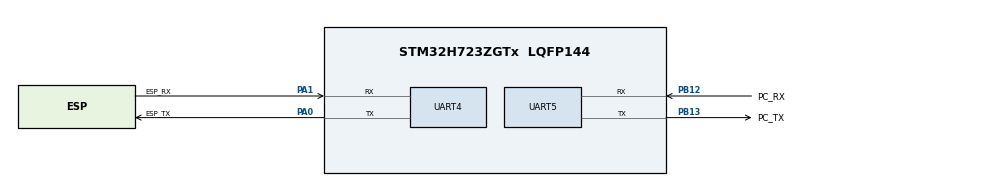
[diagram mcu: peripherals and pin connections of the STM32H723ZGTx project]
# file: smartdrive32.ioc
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CORTEX_M7.default_mode_Activation=1
Dma.Request0=UART4_RX
Dma.Request1=UART5_RX
Dma.UART4_RX.0.Direction=DMA_PERIPH_TO_MEMORY
Dma.UART4_RX.0.EventEnable=DISABLE
Dma.UART4_RX.0.FIFOMode=DMA_FIFOMODE_DISABLE
Dma.UART4_RX.0.Instance=DMA1_Stream0
Dma.UART4_RX.0.MemDataAlignment=DMA_MDATAALIGN_BYTE
Dma.UART4_RX.0.MemInc=DMA_MINC_ENABLE
Dma.UART4_RX.0.Mode=DMA_NORMAL
Dma.UART4_RX.0.PeriphDataAlignment=DMA_PDATAALIGN_BYTE
Dma.UART4_RX.0.PeriphInc=DMA_PINC_DISABLE
Dma.UART4_RX.0.Polarity=HAL_DMAMUX_REQ_GEN_RISING
Dma.UART4_RX.0.Priority=DMA_PRIORITY_LOW
Dma.UART4_RX.0.RequestNumber=1
Dma.UART4_RX.0.SignalID=NONE
Dma.UART4_RX.0.SyncEnable=DISABLE
Dma.UART4_RX.0.SyncPolarity=HAL_DMAMUX_SYNC_NO_EVENT
Dma.UART4_RX.0.SyncRequestNumber=1
Dma.UART4_RX.0.SyncSignalID=NONE
Dma.UART5_RX.1.Direction=DMA_PERIPH_TO_MEMORY
Dma.UART5_RX.1.EventEnable=DISABLE
Dma.UART5_RX.1.FIFOMode=DMA_FIFOMODE_DISABLE
Dma.UART5_RX.1.Instance=DMA1_Stream1
Dma.UART5_RX.1.MemDataAlignment=DMA_MDATAALIGN_BYTE
Dma.UART5_RX.1.MemInc=DMA_MINC_ENABLE
Dma.UART5_RX.1.Mode=DMA_NORMAL
Dma.UART5_RX.1.PeriphDataAlignment=DMA_PDATAALIGN_BYTE
Dma.UART5_RX.1.PeriphInc=DMA_PINC_DISABLE
Dma.UART5_RX.1.Polarity=HAL_DMAMUX_REQ_GEN_RISING
Dma.UART5_RX.1.Priority=DMA_PRIORITY_LOW
Dma.UART5_RX.1.RequestNumber=1
Dma.UART5_RX.1.SignalID=NONE
Dma.UART5_RX.1.SyncEnable=DISABLE
Dma.UART5_RX.1.SyncPolarity=HAL_DMAMUX_SYNC_NO_EVENT
Dma.UART5_RX.1.SyncRequestNumber=1
Dma.UART5_RX.1.SyncSignalID=NONE
Mcu.Family=STM32H7
Mcu.Name=STM32H723ZGTx
Mcu.Package=LQFP144
Mcu.UserConstants=huart_esp,$$_UART4_IP_HANDLE_$$;huart_debug,$$_UART5_IP_HANDLE_$$
NVIC.DMA1_Stream0_IRQn=true\:0\:0\:false\:false\:true\:false\:true\:true
NVIC.DMA1_Stream1_IRQn=true\:0\:0\:false\:false\:true\:false\:true\:true
NVIC.PriorityGroup=NVIC_PRIORITYGROUP_4
NVIC.UART4_IRQn=true\:0\:0\:false\:false\:true\:true\:true\:true
NVIC.UART5_IRQn=true\:0\:0\:false\:false\:true\:true\:true\:true
PA0.GPIO_Label=ESP_TX
PA0.Mode=Asynchronous
PA0.Signal=UART4_TX
PA1.GPIO_Label=ESP_RX
PA1.Mode=Asynchronous
PA1.Signal=UART4_RX
PA13(JTMS/SWDIO).Mode=Serial_Wire
PA13(JTMS/SWDIO).Signal=DEBUG_JTMS-SWDIO
PA14(JTCK/SWCLK).Mode=Serial_Wire
PA14(JTCK/SWCLK).Signal=DEBUG_JTCK-SWCLK
PB12.GPIO_Label=PC_RX
PB12.Mode=Asynchronous
PB12.Signal=UART5_RX
PB13.GPIO_Label=PC_TX
PB13.Mode=Asynchronous
PB13.Signal=UART5_TX
PH0-OSC_IN.Mode=HSE-External-Oscillator
PH0-OSC_IN.Signal=RCC_OSC_IN
PH1-OSC_OUT.Mode=HSE-External-Oscillator
PH1-OSC_OUT.Signal=RCC_OSC_OUT
ProjectManager.HeapSize=0x200
ProjectManager.StackSize=0x400
ProjectManager.TargetToolchain=STM32CubeIDE
RCC.ADCFreq_Value=50390625
RCC.APB1Freq_Value=125000000
RCC.APB2Freq_Value=125000000
RCC.APB3Freq_Value=125000000
RCC.APB4Freq_Value=125000000
RCC.CortexFreq_Value=250000000
RCC.D1PPRE=RCC_APB3_DIV2
RCC.D2PPRE1=RCC_APB1_DIV2
RCC.D2PPRE2=RCC_APB2_DIV2
RCC.D3PPRE=RCC_APB4_DIV2
RCC.DIVM1=2
RCC.DIVN1=20
RCC.DIVP1=1
RCC.HCLKFreq_Value=250000000
RCC.PLLFRACN=0
RCC.PLLSourceVirtual=RCC_PLLSOURCE_HSE
RCC.SYSCLKFreq_VALUE=250000000
RCC.SYSCLKSource=RCC_SYSCLKSOURCE_PLLCLK
RCC.USBFreq_Value=125000000
VP_MEMORYMAP_VS_MEMORYMAP.Mode=CurAppReg
board=custom

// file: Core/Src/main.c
/* USER CODE BEGIN Header */
/**
  ******************************************************************************
  * @file           : main.c
  * @brief          : Main program body
  ******************************************************************************
  * @attention
  *
  * Copyright (c) 2024 STMicroelectronics.
  * All rights reserved.
  *
  * This software is licensed under terms that can be found in the LICENSE file
  * in the root directory of this software component.
  * If no LICENSE file comes with this software, it is provided AS-IS.
  *
  ******************************************************************************
  */
/* USER CODE END Header */
#include "main.h"

UART_HandleTypeDef huart4;
UART_HandleTypeDef huart5;
DMA_HandleTypeDef hdma_uart4_rx;
DMA_HandleTypeDef hdma_uart5_rx;

void SystemClock_Config(void);
static void MPU_Config(void);
static void MX_GPIO_Init(void);
static void MX_DMA_Init(void);
static void MX_UART4_Init(void);
static void MX_UART5_Init(void);

int main(void)
{

  /* MPU Configuration--------------------------------------------------------*/
  MPU_Config();

  /* MCU Configuration--------------------------------------------------------*/

  /* Reset of all peripherals, Initializes the Flash interface and the Systick. */
  HAL_Init();

  /* Configure the system clock */
  SystemClock_Config();

  /* Initialize all configured peripherals */
  MX_GPIO_Init();
  MX_DMA_Init();
  MX_UART4_Init();
  MX_UART5_Init();
  /* USER CODE BEGIN 2 */

  // Init Debug UART DMA
  init_UART_DMA(&huart_debug, debugUartRxBuffer, RX_BUFFER_SIZE);

  // Init ESP8266 UART DMA
  init_UART_DMA(&huart_debug, espUartRxBuffer, ESP_RX_BUFFER_SIZE);

  HAL_Delay(500);
  esp_send_at_commend(&huart4);

  /* USER CODE END 2 */

  /* Infinite loop */
  /* USER CODE BEGIN WHILE */
  while (1)
  {
	  if (!rb_is_empty(&espUartRxRb)) {
		  read_and_transmit_content(&huart4, &espUartRxRb);
	  }
    /* USER CODE END WHILE */

  }
}

void SystemClock_Config(void)
{
  RCC_OscInitTypeDef RCC_OscInitStruct = {0};
  RCC_ClkInitTypeDef RCC_ClkInitStruct = {0};

  /** Supply configuration update enable
  */
  HAL_PWREx_ConfigSupply(PWR_LDO_SUPPLY);

  /** Configure the main internal regulator output voltage
  */
  __HAL_PWR_VOLTAGESCALING_CONFIG(PWR_REGULATOR_VOLTAGE_SCALE0);

  while(!__HAL_PWR_GET_FLAG(PWR_FLAG_VOSRDY)) {}

  /** Initializes the RCC Oscillators according to the specified parameters
  * in the RCC_OscInitTypeDef structure.
  */
  RCC_OscInitStruct.OscillatorType = RCC_OSCILLATORTYPE_HSE;
  RCC_OscInitStruct.HSEState = RCC_HSE_ON;
  RCC_OscInitStruct.PLL.PLLState = RCC_PLL_ON;
  RCC_OscInitStruct.PLL.PLLSource = RCC_PLLSOURCE_HSE;
  RCC_OscInitStruct.PLL.PLLM = 2;
  RCC_OscInitStruct.PLL.PLLN = 20;
  RCC_OscInitStruct.PLL.PLLP = 1;
  RCC_OscInitStruct.PLL.PLLQ = 2;
  RCC_OscInitStruct.PLL.PLLR = 2;
  RCC_OscInitStruct.PLL.PLLRGE = RCC_PLL1VCIRANGE_3;
  RCC_OscInitStruct.PLL.PLLVCOSEL = RCC_PLL1VCOWIDE;
  RCC_OscInitStruct.PLL.PLLFRACN = 0;
  if (HAL_RCC_OscConfig(&RCC_OscInitStruct) != HAL_OK)
  {
    Error_Handler();
  }

  /** Initializes the CPU, AHB and APB buses clocks
  */
  RCC_ClkInitStruct.ClockType = RCC_CLOCKTYPE_HCLK|RCC_CLOCKTYPE_SYSCLK
                              |RCC_CLOCKTYPE_PCLK1|RCC_CLOCKTYPE_PCLK2
                              |RCC_CLOCKTYPE_D3PCLK1|RCC_CLOCKTYPE_D1PCLK1;
  RCC_ClkInitStruct.SYSCLKSource = RCC_SYSCLKSOURCE_PLLCLK;
  RCC_ClkInitStruct.SYSCLKDivider = RCC_SYSCLK_DIV1;
  RCC_ClkInitStruct.AHBCLKDivider = RCC_HCLK_DIV1;
  RCC_ClkInitStruct.APB3CLKDivider = RCC_APB3_DIV2;
  RCC_ClkInitStruct.APB1CLKDivider = RCC_APB1_DIV2;
  RCC_ClkInitStruct.APB2CLKDivider = RCC_APB2_DIV2;
  RCC_ClkInitStruct.APB4CLKDivider = RCC_APB4_DIV2;

  if (HAL_RCC_ClockConfig(&RCC_ClkInitStruct, FLASH_LATENCY_3) != HAL_OK)
  {
    Error_Handler();
  }
}

static void MX_UART4_Init(void)
{

  huart4.Instance = UART4;
  huart4.Init.BaudRate = 115200;
  huart4.Init.WordLength = UART_WORDLENGTH_8B;
  huart4.Init.StopBits = UART_STOPBITS_1;
  huart4.Init.Parity = UART_PARITY_NONE;
  huart4.Init.Mode = UART_MODE_TX_RX;
  huart4.Init.HwFlowCtl = UART_HWCONTROL_NONE;
  huart4.Init.OverSampling = UART_OVERSAMPLING_16;
  huart4.Init.OneBitSampling = UART_ONE_BIT_SAMPLE_DISABLE;
  huart4.Init.ClockPrescaler = UART_PRESCALER_DIV1;
  huart4.AdvancedInit.AdvFeatureInit = UART_ADVFEATURE_NO_INIT;
  if (HAL_UART_Init(&huart4) != HAL_OK)
  {
    Error_Handler();
  }
  if (HAL_UARTEx_SetTxFifoThreshold(&huart4, UART_TXFIFO_THRESHOLD_1_8) != HAL_OK)
  {
    Error_Handler();
  }
  if (HAL_UARTEx_SetRxFifoThreshold(&huart4, UART_RXFIFO_THRESHOLD_1_8) != HAL_OK)
  {
    Error_Handler();
  }
  if (HAL_UARTEx_DisableFifoMode(&huart4) != HAL_OK)
  {
    Error_Handler();
  }

}

static void MX_UART5_Init(void)
{

  huart5.Instance = UART5;
  huart5.Init.BaudRate = 115200;
  huart5.Init.WordLength = UART_WORDLENGTH_8B;
  huart5.Init.StopBits = UART_STOPBITS_1;
  huart5.Init.Parity = UART_PARITY_NONE;
  huart5.Init.Mode = UART_MODE_TX_RX;
  huart5.Init.HwFlowCtl = UART_HWCONTROL_NONE;
  huart5.Init.OverSampling = UART_OVERSAMPLING_16;
  huart5.Init.OneBitSampling = UART_ONE_BIT_SAMPLE_DISABLE;
  huart5.Init.ClockPrescaler = UART_PRESCALER_DIV1;
  huart5.AdvancedInit.AdvFeatureInit = UART_ADVFEATURE_NO_INIT;
  if (HAL_UART_Init(&huart5) != HAL_OK)
  {
    Error_Handler();
  }
  if (HAL_UARTEx_SetTxFifoThreshold(&huart5, UART_TXFIFO_THRESHOLD_1_8) != HAL_OK)
  {
    Error_Handler();
  }
  if (HAL_UARTEx_SetRxFifoThreshold(&huart5, UART_RXFIFO_THRESHOLD_1_8) != HAL_OK)
  {
    Error_Handler();
  }
  if (HAL_UARTEx_DisableFifoMode(&huart5) != HAL_OK)
  {
    Error_Handler();
  }

}

static void MX_DMA_Init(void)
{

  /* DMA controller clock enable */
  __HAL_RCC_DMA1_CLK_ENABLE();

  /* DMA interrupt init */
  /* DMA1_Stream0_IRQn interrupt configuration */
  HAL_NVIC_SetPriority(DMA1_Stream0_IRQn, 0, 0);
  HAL_NVIC_EnableIRQ(DMA1_Stream0_IRQn);
  /* DMA1_Stream1_IRQn interrupt configuration */
  HAL_NVIC_SetPriority(DMA1_Stream1_IRQn, 0, 0);
  HAL_NVIC_EnableIRQ(DMA1_Stream1_IRQn);

}

static void MX_GPIO_Init(void)
{

  /* GPIO Ports Clock Enable */
  __HAL_RCC_GPIOH_CLK_ENABLE();
  __HAL_RCC_GPIOA_CLK_ENABLE();
  __HAL_RCC_GPIOB_CLK_ENABLE();

}

 /* MPU Configuration */

void MPU_Config(void)
{
  MPU_Region_InitTypeDef MPU_InitStruct = {0};

  /* Disables the MPU */
  HAL_MPU_Disable();

  /** Initializes and configures the Region and the memory to be protected
  */
  MPU_InitStruct.Enable = MPU_REGION_ENABLE;
  MPU_InitStruct.Number = MPU_REGION_NUMBER0;
  MPU_InitStruct.BaseAddress = 0x0;
  MPU_InitStruct.Size = MPU_REGION_SIZE_4GB;
  MPU_InitStruct.SubRegionDisable = 0x87;
  MPU_InitStruct.TypeExtField = MPU_TEX_LEVEL0;
  MPU_InitStruct.AccessPermission = MPU_REGION_NO_ACCESS;
  MPU_InitStruct.DisableExec = MPU_INSTRUCTION_ACCESS_DISABLE;
  MPU_InitStruct.IsShareable = MPU_ACCESS_SHAREABLE;
  MPU_InitStruct.IsCacheable = MPU_ACCESS_NOT_CACHEABLE;
  MPU_InitStruct.IsBufferable = MPU_ACCESS_NOT_BUFFERABLE;

  HAL_MPU_ConfigRegion(&MPU_InitStruct);
  /* Enables the MPU */
  HAL_MPU_Enable(MPU_PRIVILEGED_DEFAULT);

}

void Error_Handler(void)
{
  __disable_irq();
  while (1)
  {
  }
}
